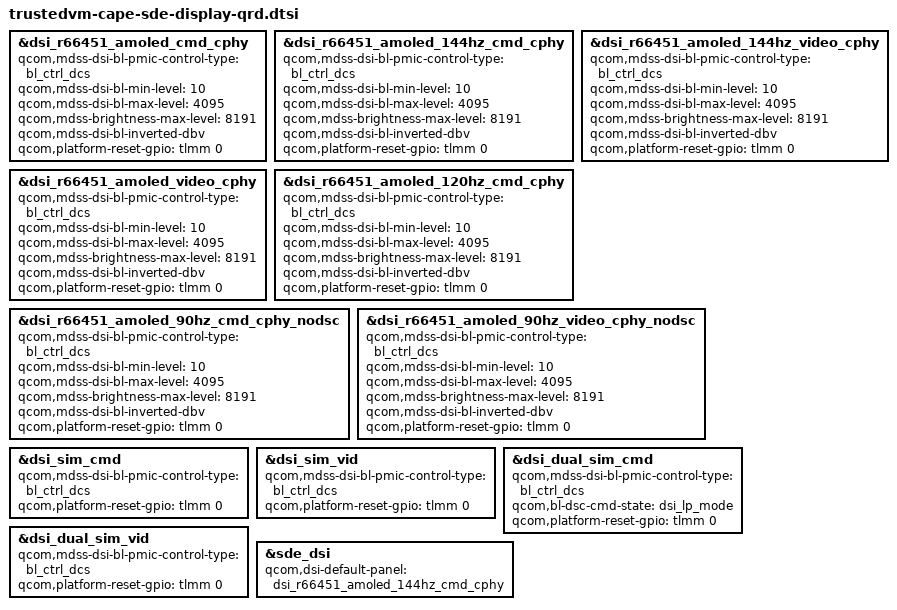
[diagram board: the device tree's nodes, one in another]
#include "trustedvm-cape-sde-display.dtsi"

&dsi_r66451_amoled_cmd_cphy {
	qcom,mdss-dsi-bl-pmic-control-type = "bl_ctrl_dcs";
	qcom,mdss-dsi-bl-min-level = <10>;
	qcom,mdss-dsi-bl-max-level = <4095>;
	qcom,mdss-brightness-max-level = <8191>;
	qcom,mdss-dsi-bl-inverted-dbv;
	qcom,platform-reset-gpio = <&tlmm 0 0>;
};

&dsi_r66451_amoled_144hz_cmd_cphy {
	qcom,mdss-dsi-bl-pmic-control-type = "bl_ctrl_dcs";
	qcom,mdss-dsi-bl-min-level = <10>;
	qcom,mdss-dsi-bl-max-level = <4095>;
	qcom,mdss-brightness-max-level = <8191>;
	qcom,mdss-dsi-bl-inverted-dbv;
	qcom,platform-reset-gpio = <&tlmm 0 0>;
};

&dsi_r66451_amoled_144hz_video_cphy {
	qcom,mdss-dsi-bl-pmic-control-type = "bl_ctrl_dcs";
	qcom,mdss-dsi-bl-min-level = <10>;
	qcom,mdss-dsi-bl-max-level = <4095>;
	qcom,mdss-brightness-max-level = <8191>;
	qcom,mdss-dsi-bl-inverted-dbv;
	qcom,platform-reset-gpio = <&tlmm 0 0>;
};

&dsi_r66451_amoled_video_cphy {
	qcom,mdss-dsi-bl-pmic-control-type = "bl_ctrl_dcs";
	qcom,mdss-dsi-bl-min-level = <10>;
	qcom,mdss-dsi-bl-max-level = <4095>;
	qcom,mdss-brightness-max-level = <8191>;
	qcom,mdss-dsi-bl-inverted-dbv;
	qcom,platform-reset-gpio = <&tlmm 0 0>;
};

&dsi_r66451_amoled_120hz_cmd_cphy {
	qcom,mdss-dsi-bl-pmic-control-type = "bl_ctrl_dcs";
	qcom,mdss-dsi-bl-min-level = <10>;
	qcom,mdss-dsi-bl-max-level = <4095>;
	qcom,mdss-brightness-max-level = <8191>;
	qcom,mdss-dsi-bl-inverted-dbv;
	qcom,platform-reset-gpio = <&tlmm 0 0>;
};

&dsi_r66451_amoled_90hz_cmd_cphy_nodsc {
	qcom,mdss-dsi-bl-pmic-control-type = "bl_ctrl_dcs";
	qcom,mdss-dsi-bl-min-level = <10>;
	qcom,mdss-dsi-bl-max-level = <4095>;
	qcom,mdss-brightness-max-level = <8191>;
	qcom,mdss-dsi-bl-inverted-dbv;
	qcom,platform-reset-gpio = <&tlmm 0 0>;
};

&dsi_r66451_amoled_90hz_video_cphy_nodsc {
	qcom,mdss-dsi-bl-pmic-control-type = "bl_ctrl_dcs";
	qcom,mdss-dsi-bl-min-level = <10>;
	qcom,mdss-dsi-bl-max-level = <4095>;
	qcom,mdss-brightness-max-level = <8191>;
	qcom,mdss-dsi-bl-inverted-dbv;
	qcom,platform-reset-gpio = <&tlmm 0 0>;
};

&dsi_sim_cmd {
	qcom,mdss-dsi-bl-pmic-control-type = "bl_ctrl_dcs";
	qcom,platform-reset-gpio = <&tlmm 0 0>;
};

&dsi_sim_vid {
	qcom,mdss-dsi-bl-pmic-control-type = "bl_ctrl_dcs";
	qcom,platform-reset-gpio = <&tlmm 0 0>;
};

&dsi_dual_sim_cmd {
	qcom,mdss-dsi-bl-pmic-control-type = "bl_ctrl_dcs";
	qcom,bl-dsc-cmd-state = "dsi_lp_mode";
	qcom,platform-reset-gpio = <&tlmm 0 0>;
};

&dsi_dual_sim_vid {
	qcom,mdss-dsi-bl-pmic-control-type = "bl_ctrl_dcs";
	qcom,platform-reset-gpio = <&tlmm 0 0>;
};

&sde_dsi {
	qcom,dsi-default-panel = <&dsi_r66451_amoled_144hz_cmd_cphy>;
};
